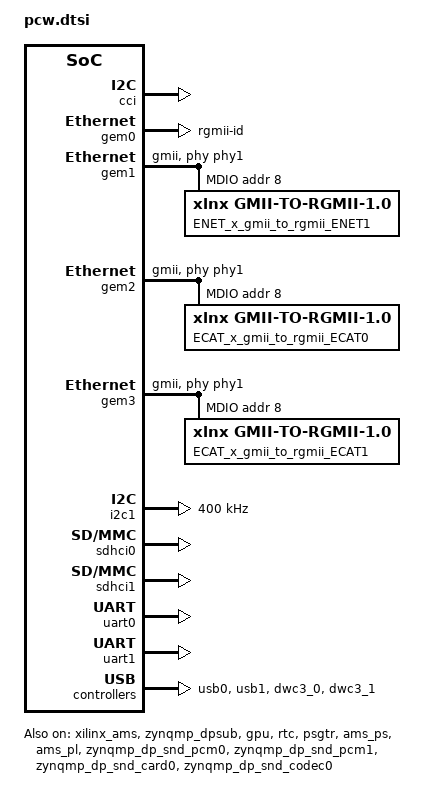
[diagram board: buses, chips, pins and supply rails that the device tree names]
/*
 * CAUTION: This file is automatically generated by Xilinx.
 * Version:  
 * Today is: Sat Aug 20 15:46:44 2022
 */


&gic {
	num_cpus = <2>;
	num_interrupts = <96>;
};
&lpd_dma_chan1 {
	status = "okay";
};
&lpd_dma_chan2 {
	status = "okay";
};
&lpd_dma_chan3 {
	status = "okay";
};
&lpd_dma_chan4 {
	status = "okay";
};
&lpd_dma_chan5 {
	status = "okay";
};
&lpd_dma_chan6 {
	status = "okay";
};
&lpd_dma_chan7 {
	status = "okay";
};
&lpd_dma_chan8 {
	status = "okay";
};
&xilinx_ams {
	status = "okay";
};
&cci {
	status = "okay";
};
&zynqmp_dpsub {
	phy-names = "dp-phy0","dp-phy1";
	phys = <&psgtr 1 6 0 3>, <&psgtr 0 6 1 3>;
	status = "okay";
	xlnx,max-lanes = <2>;
};
&zynqmp_dpdma {
	status = "okay";
};
&gem0 {
	phy-mode = "rgmii-id";
	status = "okay";
	xlnx,ptp-enet-clock = <0x0>;
};
&gem1 {
	phy-handle = <&phy1>;
	phy-mode = "gmii";
	status = "okay";
	xlnx,ptp-enet-clock = <0x0>;
	psu_ethernet_1_mdio: mdio {
		#address-cells = <1>;
		#size-cells = <0>;
		ENET_x_gmii_to_rgmii_ENET1: ENET_x_gmii_to_rgmii_ENET1@8 {
			compatible = "xlnx,gmii-to-rgmii-1.0";
			phy-handle = <&phy1>;
			reg = <8>;
		};
	};
};
&gem2 {
	phy-handle = <&phy1>;
	phy-mode = "gmii";
	status = "okay";
	xlnx,ptp-enet-clock = <0x0>;
	psu_ethernet_2_mdio: mdio {
		#address-cells = <1>;
		#size-cells = <0>;
		ECAT_x_gmii_to_rgmii_ECAT0: ECAT_x_gmii_to_rgmii_ECAT0@8 {
			compatible = "xlnx,gmii-to-rgmii-1.0";
			phy-handle = <&phy1>;
			reg = <8>;
		};
	};
};
&gem3 {
	phy-handle = <&phy1>;
	phy-mode = "gmii";
	status = "okay";
	xlnx,ptp-enet-clock = <0x0>;
	psu_ethernet_3_mdio: mdio {
		#address-cells = <1>;
		#size-cells = <0>;
		ECAT_x_gmii_to_rgmii_ECAT1: ECAT_x_gmii_to_rgmii_ECAT1@8 {
			compatible = "xlnx,gmii-to-rgmii-1.0";
			phy-handle = <&phy1>;
			reg = <8>;
		};
	};
};
&fpd_dma_chan1 {
	status = "okay";
};
&fpd_dma_chan2 {
	status = "okay";
};
&fpd_dma_chan3 {
	status = "okay";
};
&fpd_dma_chan4 {
	status = "okay";
};
&fpd_dma_chan5 {
	status = "okay";
};
&fpd_dma_chan6 {
	status = "okay";
};
&fpd_dma_chan7 {
	status = "okay";
};
&fpd_dma_chan8 {
	status = "okay";
};
&gpio {
	emio-gpio-width = <32>;
	gpio-mask-high = <0x0>;
	gpio-mask-low = <0x5600>;
	status = "okay";
};
&gpu {
	status = "okay";
	xlnx,tz-nonsecure = <0x1>;
};
&i2c1 {
	clock-frequency = <400000>;
	status = "okay";
};
&rtc {
	status = "okay";
};
&sdhci0 {
	clock-frequency = <187500000>;
	status = "okay";
	xlnx,mio-bank = <0x0>;
};
&sdhci1 {
	clock-frequency = <187500000>;
	status = "okay";
	xlnx,mio-bank = <0x1>;
};
&psgtr {
	status = "okay";
};
&uart0 {
	cts-override ;
	device_type = "serial";
	port-number = <2>;
	status = "okay";
	u-boot,dm-pre-reloc ;
};
&uart1 {
	cts-override ;
	device_type = "serial";
	port-number = <3>;
	status = "okay";
	u-boot,dm-pre-reloc ;
};
&usb0 {
	status = "okay";
	xlnx,tz-nonsecure = <0x1>;
	xlnx,usb-polarity = <0x0>;
	xlnx,usb-reset-mode = <0x0>;
};
&usb1 {
	status = "okay";
	xlnx,tz-nonsecure = <0x0>;
	xlnx,usb-polarity = <0x0>;
	xlnx,usb-reset-mode = <0x0>;
};
&dwc3_0 {
	status = "okay";
};
&dwc3_1 {
	status = "okay";
};
&pss_ref_clk {
	clock-frequency = <33333333>;
};
&video_clk {
	clock-frequency = <33333000>;
};
&pinctrl0 {
	gem3-default {
		/delete-node/ conf ;
		/delete-node/ conf-mdio ;
		/delete-node/ conf-rx ;
		/delete-node/ conf-tx ;
		/delete-node/ mux ;
		/delete-node/ mux-mdio ;
	};
};
&ams_ps {
	status = "okay";
};
&ams_pl {
	status = "okay";
};
&zynqmp_dp_snd_pcm0 {
	status = "okay";
};
&zynqmp_dp_snd_pcm1 {
	status = "okay";
};
&zynqmp_dp_snd_card0 {
	status = "okay";
};
&zynqmp_dp_snd_codec0 {
	status = "okay";
};
